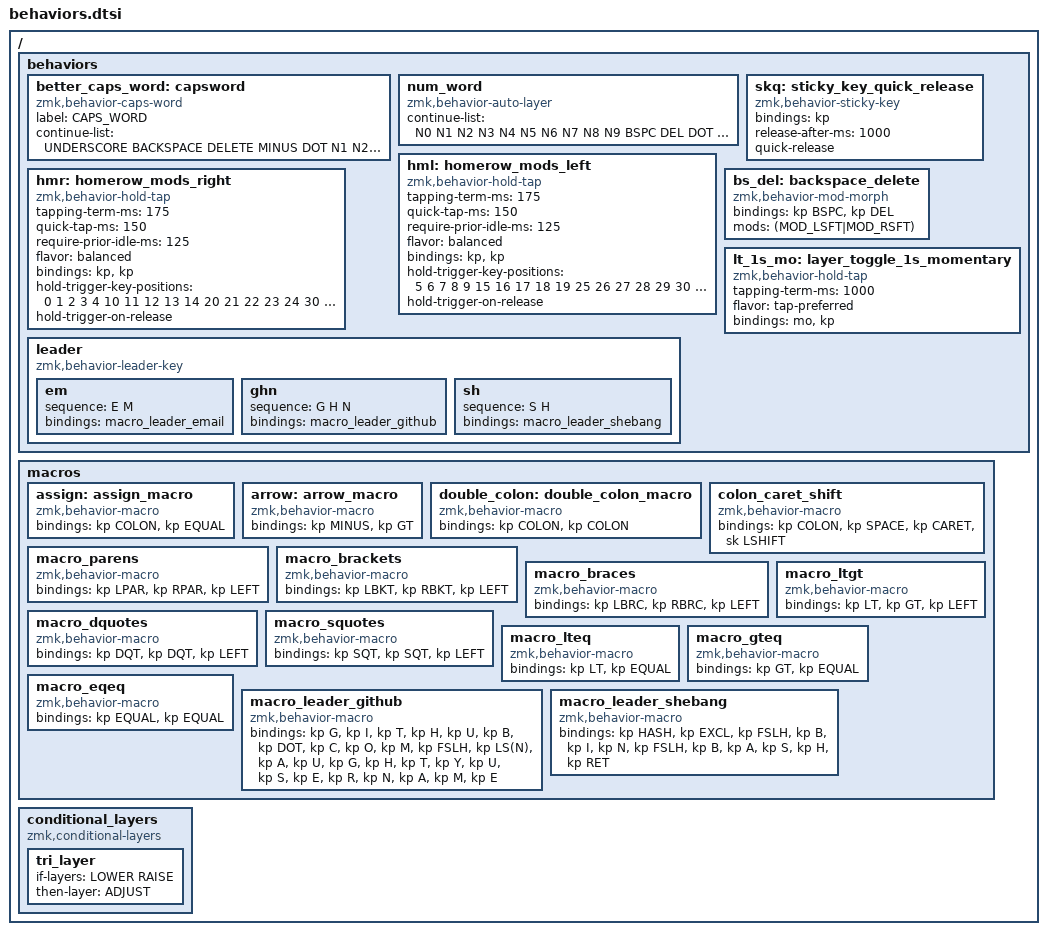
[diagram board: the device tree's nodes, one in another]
#include "wrappers.dtsi"
#include "secrets.dtsi"
// clang-format off

/ {
    behaviors {
// =====================================================================================
// CUSTOM BEHAVIOR CHANGES THAT HOPEFULLY WORK
// =====================================================================================

// caps word continue list
    better_caps_word: capsword {
            compatible = "zmk,behavior-caps-word";
            label = "CAPS_WORD";
            #binding-cells = <0>;
            // expand the list to all the keys that you want caps word to not stop capping on
            // default is all the alphas and _ but it lacked minus which is annoying.
            continue-list = <UNDERSCORE BACKSPACE DELETE MINUS DOT N1 N2 N3 N4 N5 N6 N7 N8 N9 N0
                >;
        };

        // caps_word_invert_on_shift lets it stay active while we un-caps while holding shift
        // might be useful with shift+bspc=del, worth consideration

// NUM word
    num_word: num_word {
        compatible = "zmk,behavior-auto-layer";
        #binding-cells =<1>;
        continue-list = <
            N0 N1 N2 N3 N4 N5 N6 N7 N8 N9
            BSPC DEL DOT COMMA
            PLUS MINUS STAR FSLH EQUAL UNDER
            >;
    };

// sticky keys fix - they linger on to long / i type to fast, ie. 2 keys get shifted or
// whatever modifier when its only supposed to be one
skq: sticky_key_quick_release {
            compatible = "zmk,behavior-sticky-key";
            #binding-cells = <1>;
            bindings = <&kp>;
            release-after-ms = <1000>; // Duration until it turns off i see a lot of 1200-1500 from other users here
            quick-release;             // This lets us NOt haave that double caps happen
                                       //              ^^^
        };

// =====================================================================================
// HOME_ROW_MODS
// =====================================================================================
        // we might need slightly less quick tap terms
        // also double check the hold-trigger positions again.
        // possible also we ditch balanced and go for tap-preferred.

        hml: homerow_mods_left {
            compatible = "zmk,behavior-hold-tap";
            #binding-cells = <2>;
            tapping-term-ms = <175>;
            quick-tap-ms = <150>;
            require-prior-idle-ms = <125>;
            flavor = "balanced";
            // hold-while-undecided;
            bindings = <&kp>, <&kp>;
            hold-trigger-key-positions = <5 6 7 8 9 15 16 17 18 19 25 26 27 28 29 30 31 32 33>;
            hold-trigger-on-release;
        };

        hmr: homerow_mods_right {
            compatible = "zmk,behavior-hold-tap";
            #binding-cells = <2>;
            tapping-term-ms = <175>;
            quick-tap-ms = <150>;
            require-prior-idle-ms = <125>;
            flavor = "balanced";
            // hold-while-undecided;
            bindings = <&kp>, <&kp>;
            hold-trigger-key-positions = <0 1 2 3 4 10 11 12 13 14 20 21 22 23 24 30 31 32 33>;
            hold-trigger-on-release;
        };

        bs_del: backspace_delete {
            compatible = "zmk,behavior-mod-morph";
            #binding-cells = <0>;
            bindings = <&kp BSPC>, <&kp DEL>;
            mods = <(MOD_LSFT|MOD_RSFT)>;
        };

        lt_1s_mo: layer_toggle_1s_momentary {
            compatible = "zmk,behavior-hold-tap";
            #binding-cells = <2>; // For Layer and Keycode
            tapping-term-ms = <1000>; // 1 second hold
            flavor = "tap-preferred"; // Tap for keycode, hold for layer
            bindings = <&mo>, <&kp>; // Hold binding (&mo) and Tap binding (&kp)
        };

// =====================================================================================
// LEADER KEY BEHAVIOR
// =====================================================================================
        leader: leader {
            compatible = "zmk,behavior-leader-key";
            #binding-cells = <0>;

            // Leader sequences - GB combo triggers, then type sequence keys
            em {
                sequence = <E M>;
                bindings = <&macro_leader_email>;
            };
            ghn {
                sequence = <G H N>;
                bindings = <&macro_leader_github>;
            };
            sh {
                sequence = <S H>;
                bindings = <&macro_leader_shebang>;
            };
        };
    };
// =====================================================================================
// MACROS
// =====================================================================================
    macros {
        assign: assign_macro {
            compatible = "zmk,behavior-macro";
            #binding-cells = <0>;
            bindings = <&kp COLON &kp EQUAL>;
        };
        arrow: arrow_macro {
            compatible = "zmk,behavior-macro";
            #binding-cells = <0>;
            bindings = <&kp MINUS &kp GT>;
        };
        double_colon: double_colon_macro {
            compatible = "zmk,behavior-macro";
            #binding-cells = <0>;
            bindings = <&kp COLON &kp COLON>;
        };

        // Colon-Caret-Shift: sends ": ^" then one-shot shift for pointer casing (Pointer_Name)
        colon_caret_shift: colon_caret_shift { // : ^ + one-shot shift
            compatible = "zmk,behavior-macro";
            #binding-cells = <0>;
            bindings = <&kp COLON &kp SPACE &kp CARET &sk LSHIFT>;
        };

        // pairing combos
        // Types "()" and places cursor in the middle
        macro_parens: macro_parens {
           compatible = "zmk,behavior-macro";
          #binding-cells = <0>;
          bindings = <&kp LPAR &kp RPAR &kp LEFT>;
        };
        // Types "[]" and places cursor in the middle
        macro_brackets: macro_brackets {
            compatible = "zmk,behavior-macro";
            #binding-cells = <0>;
            bindings = <&kp LBKT &kp RBKT &kp LEFT>;
        };
        // Types "{}" and places cursor in the middle
        macro_braces: macro_braces {
          compatible = "zmk,behavior-macro";
          #binding-cells = <0>;
          bindings = <&kp LBRC &kp RBRC &kp LEFT>;
        };
        // Types "<>" and places cursor in the middle
        macro_ltgt: macro_ltgt {
          compatible = "zmk,behavior-macro";
          #binding-cells = <0>;
          bindings = <&kp LT &kp GT &kp LEFT>;
        };
        macro_dquotes: macro_dquotes {
            compatible = "zmk,behavior-macro";
            #binding-cells = <0>;
            bindings = <&kp DQT &kp DQT &kp LEFT>;
        };
        macro_squotes: macro_squotes {
            compatible = "zmk,behavior-macro";
            #binding-cells = <0>;
            bindings = <&kp SQT &kp SQT &kp LEFT>;
        };
        // Comparison operator macros
        macro_lteq: macro_lteq {
            compatible = "zmk,behavior-macro";
            #binding-cells = <0>;
            bindings = <&kp LT &kp EQUAL>;  // <=
        };
        macro_gteq: macro_gteq {
            compatible = "zmk,behavior-macro";
            #binding-cells = <0>;
            bindings = <&kp GT &kp EQUAL>;  // >=
        };
        macro_eqeq: macro_eqeq {
            compatible = "zmk,behavior-macro";
            #binding-cells = <0>;
            bindings = <&kp EQUAL &kp EQUAL>;  // ==
        };

// =====================================================================================
// LEADER KEY SEQUENCE MACROS
// =====================================================================================
        // Note: Email macro (EM sequence) is in secrets.dtsi

        // GHN sequence - GitHub URL (public, safe to commit)
        macro_leader_github: macro_leader_github {
            compatible = "zmk,behavior-macro";
            #binding-cells = <0>;
            bindings = <&kp G &kp I &kp T &kp H &kp U &kp B &kp DOT &kp C &kp O &kp M
                        &kp FSLH &kp LS(N) &kp A &kp U &kp G &kp H &kp T &kp Y &kp U
                        &kp S &kp E &kp R &kp N &kp A &kp M &kp E>;
        };

        // SH sequence - Bash shebang
        macro_leader_shebang: macro_leader_shebang {
            compatible = "zmk,behavior-macro";
            #binding-cells = <0>;
            bindings = <&kp HASH &kp EXCL &kp FSLH &kp B &kp I &kp N &kp FSLH
                        &kp B &kp A &kp S &kp H &kp RET>;
        };
};

// =====================================================================================
// TRI_LAYER_STUFF
// =====================================================================================
    conditional_layers {
        compatible = "zmk,conditional-layers";
        tri_layer {
            if-layers = <LOWER RAISE>;
            then-layer = <ADJUST>;
        };
    };
};
